# Q32M210 register map
File version: 1.0
Registers are 32-bit, read-write, no defined reset value unless marked. A register's access mark holds for its fields unless they carry their own. Offsets are from the block's base; [hi:lo] are bit positions; lines under a group give offsets from that group; {n}, {i} and the like mark numbered series.

## Nested_Vector_Interrupt_Controller
Base 0xE000E004
0x00 NVIC_INT_TYPE — NVIC Interrupt Controller Type Register
  [4:0] INTLINESNUM — Number of interrupt inputs in steps of 32
    1=NVIC_INTLINESNUM_33_64 (33 to 64 interrupt inputs)
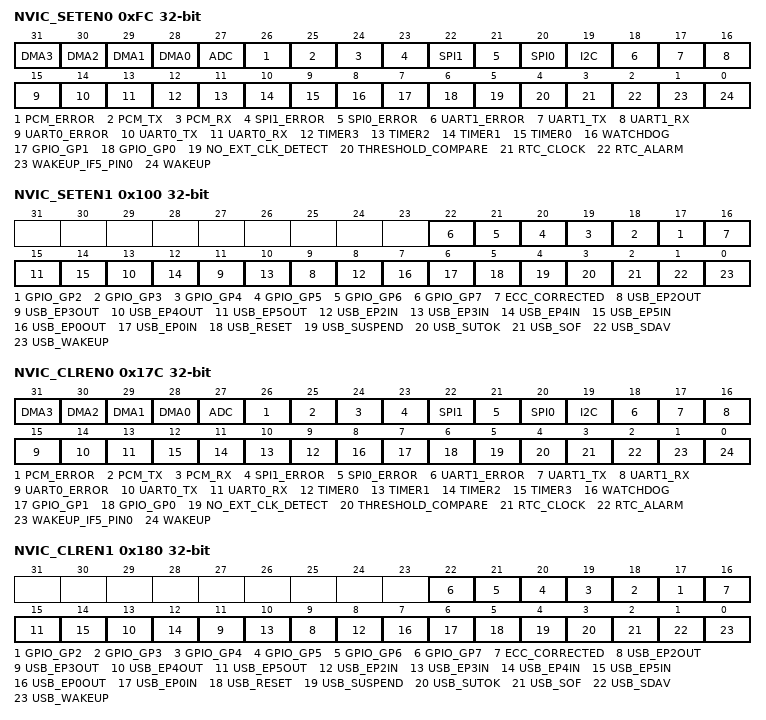
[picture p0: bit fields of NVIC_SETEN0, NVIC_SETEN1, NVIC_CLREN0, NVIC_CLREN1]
0xFC NVIC_SETEN0 — NVIC External Interrupt Set Enable Register 0
  [n+28] DMA{n} (n=0..3) — DMA channel {n} interrupt set enable
    1=NVIC_DMA{n}_INT_ENABLE (Enable DMA channel {n} interrupt)
  [27] ADC — ADC interrupt set enable
    1=NVIC_ADC_INT_ENABLE (Enable ADC0interrupt)
  [26] PCM_ERROR — PCM buffer overflow/underrun interrupt set enable
    1=NVIC_PCM_ERROR_INT_ENABLE (Enable PCM error interrupt)
  [25] PCM_TX — PCM transmit interrupt set enable
    1=NVIC_PCM_TX_INT_ENABLE (Enable PCM TX interrupt)
  [24] PCM_RX — PCM receive interrupt set enable
    1=NVIC_PCM_RX_INT_ENABLE (Enable PCM RX interrupt)
  [23] SPI1_ERROR — SPI1 buffer overflow/underrun error interrupt set enable
    1=NVIC_SPI1_ERROR_INT_ENABLE (Enable SPI1 error interrupt)
  [22] SPI1 — SPI1 interrupt set enable
    1=NVIC_SPI1_INT_ENABLE (Enable SPI1 interrupt)
  [21] SPI0_ERROR — SPI0 buffer overflow/underrun error interrupt set enable
    1=NVIC_SPI0_ERROR_INT_ENABLE (Enable SPI0 error interrupt)
  [20] SPI0 — SPI0 interrupt set enable
    1=NVIC_SPI0_INT_ENABLE (Enable SPI0 interrupt)
  [19] I2C — I2C interrupt set enable
    1=NVIC_I2C_INT_ENABLE (Enable I2C interrupt)
  [18] UART1_ERROR — UART1 buffer overflow/underrun error interrupt set enable
    1=NVIC_UART1_ERROR_INT_ENABLE (Enable UART1 error interrupt)
  [17] UART1_TX — UART1 transmit interrupt set enable
    1=NVIC_UART1_TX_INT_ENABLE (Enable UART1 transmit interrupt)
  [16] UART1_RX — UART1 receive interrupt set enable
    1=NVIC_UART1_RX_INT_ENABLE (Enable UART1 receive interrupt)
  [15] UART0_ERROR — UART0 buffer overflow/underrun error interrupt set enable
    1=NVIC_UART0_ERROR_INT_ENABLE (Enable UART0 error interrupt)
  [14] UART0_TX — UART0 transmit interrupt set enable
    1=NVIC_UART0_TX_INT_ENABLE (Enable UART0 transmit interrupt)
  [13] UART0_RX — UART0 receive interrupt set enable
    1=NVIC_UART0_RX_INT_ENABLE (Enable UART0 receive interrupt)
  [12] TIMER3 — TIMER1 interrupt set enable
    1=NVIC_TIMER3_INT_ENABLE (Enable TIMER1 interrupt)
  [11] TIMER2 — TIMER0 interrupt set enable
    1=NVIC_TIMER2_INT_ENABLE (Enable TIMER0 interrupt)
  [10] TIMER1 — TIMER1 interrupt set enable
    1=NVIC_TIMER1_INT_ENABLE (Enable TIMER1 interrupt)
  [9] TIMER0 — TIMER0 interrupt set enable
    1=NVIC_TIMER0_INT_ENABLE (Enable TIMER0 interrupt)
  [8] WATCHDOG — Watchdog interrupt set enable
    1=NVIC_WATCHDOG_INT_ENABLE (Enable watchdog interrupt)
  [7] GPIO_GP1 — GPIO_GP1 interrupt set enable
    1=NVIC_GPIO_GP1_INT_ENABLE (Enable GPIO_GP1 interrupt)
  [6] GPIO_GP0 — GPIO_GP0 interrupt set enable
    1=NVIC_GPIO_GP0_INT_ENABLE (Enable GPIO_GP0 interrupt)
  [5] NO_EXT_CLK_DETECT — No external clock interrupt set enable
    1=NVIC_NO_EXT_CLK_DETECT_INT_ENABLE (Enable no external clock interrupt)
  [4] THRESHOLD_COMPARE — Threshold compare interrupt set enable
    1=NVIC_THRESHOLD_COMPARE_INT_ENABLE (Enable threshold compare interrupt)
  [3] RTC_CLOCK — RTC clock interrupt set enable
    1=NVIC_RTC_CLOCK_INT_ENABLE (Enable RTC clock interrupt)
  [2] RTC_ALARM — RTC alarm interrupt set enable
    1=NVIC_RTC_ALARM_INT_ENABLE (Enable RTC alarm interrupt)
  [1] WAKEUP_IF5_PIN0 — Analog wakeup interrupt set enable
    1=NVIC_WAKEUP_IF5_PIN0_INT_ENABLE (Enable analog wakeup interrupt)
  [0] WAKEUP — Wakeup interrupt set enable
    1=NVIC_WAKEUP_INT_ENABLE (Enable wakeup interrupt)
0x100 NVIC_SETEN1 — NVIC External Interrupt Set Enable Register 1
  [n+15] GPIO_GP{n} (n=2..7) — GPIO_GP{n} interrupt set enable
    1=NVIC_GPIO_GP{n}_INT_ENABLE (Enable GPIO_GP{n} interrupt)
  [16] ECC_CORRECTED — ECC error corrected interrupt set enable
    1=NVIC_ECC_CORRECTED_INT_ENABLE (Enable the ECC error corrected interrupt)
  [2n+5] USB_EP{n}OUT (n=2..5) — USB EP{n}OUT interrupt set enable
    1=NVIC_USB_EP{n}OUT_INT_ENABLE (Enable USB EP{n}OUT interrupt)
  [2n+4] USB_EP{n}IN (n=2..5) — USB EP{n}IN interrupt set enable
    1=NVIC_USB_EP{n}IN_INT_ENABLE (Enable USB EP{n}IN interrupt)
  [7] USB_EP0OUT — USB EP0OUT interrupt set enable
    1=NVIC_USB_EP0OUT_INT_ENABLE (Enable USB EP0OUT interrupt)
  [6] USB_EP0IN — USB EP0IN interrupt set enable
    1=NVIC_USB_EP0IN_INT_ENABLE (Enable USB EP0IN interrupt)
  [5] USB_RESET — USB reset interrupt set enable
    1=NVIC_USB_RESET_INT_ENABLE (Enable USB reset interrupt)
  [4] USB_SUSPEND — USB suspend interrupt set enable
    1=NVIC_USB_SUSPEND_INT_ENABLE (Enable USB suspend interrupt)
  [3] USB_SUTOK — USB setup data loading interrupt set enable
    1=NVIC_USB_SUTOK_INT_ENABLE (Enable USB setup data loading interrupt)
  [2] USB_SOF — USB start of frame interrupt set enable
    1=NVIC_USB_SOF_INT_ENABLE (Enable USB start of frame interrupt)
  [1] USB_SDAV — USB setup data available interrupt set enable
    1=NVIC_USB_SDAV_INT_ENABLE (Enable USB setup data available interrupt)
  [0] USB_WAKEUP — USB wakeup interrupt set enable
    1=NVIC_USB_WAKEUP_INT_ENABLE (Enable USB wakeup interrupt)
0x17C NVIC_CLREN0 — NVIC External Interrupt Clear Enable Register 0
  [n+28] DMA{n} (n=0..3) — DMA channel {n} interrupt clear enable
    1=NVIC_DMA{n}_INT_DISABLE (Disable DMA channel {n} interrupt)
  [27] ADC — ADC interrupt clear enable
    1=NVIC_ADC_INT_DISABLE (Disable ADC interrupt)
  [26] PCM_ERROR — PCM buffer overflow/underrun interrupt clear enable
    1=NVIC_PCM_ERROR_INT_DISABLE (Disable PCM error interrupt)
  [25] PCM_TX — PCM transmit interrupt clear enable
    1=NVIC_PCM_TX_INT_DISABLE (Disable PCM TX interrupt)
  [24] PCM_RX — PCM receive interrupt clear enable
    1=NVIC_PCM_RX_INT_DISABLE (Disable PCM RX interrupt)
  [23] SPI1_ERROR — SPI1 buffer overflow/underrun error interrupt clear enable
    1=NVIC_SPI1_ERROR_INT_DISABLE (Disable SPI1 error interrupt)
  [22] SPI1 — SPI1 interrupt clear enable
    1=NVIC_SPI1_INT_DISABLE (Disable SPI1 interrupt)
  [21] SPI0_ERROR — SPI0 buffer overflow/underrun error interrupt clear enable
    1=NVIC_SPI0_ERROR_INT_DISABLE (Disable SPI0 error interrupt)
  [20] SPI0 — SPI0 interrupt clear enable
    1=NVIC_SPI0_INT_DISABLE (Disable SPI0 interrupt)
  [19] I2C — I2C interrupt clear enable
    1=NVIC_I2C_INT_DISABLE (Disable I2C interrupt)
  [18] UART1_ERROR — UART1 buffer overflow/underrun error interrupt clear enable
    1=NVIC_UART1_ERROR_INT_DISABLE (Disable UART1 error interrupt)
  [17] UART1_TX — UART1 transmit interrupt clear enable
    1=NVIC_UART1_TX_INT_DISABLE (Disable UART1 transmit interrupt)
  [16] UART1_RX — UART1 receive interrupt clear enable
    1=NVIC_UART1_RX_INT_DISABLE (Disable UART1 receive interrupt)
  [15] UART0_ERROR — UART0 buffer overflow/underrun error interrupt clear enable
    1=NVIC_UART0_ERROR_INT_DISABLE (Disable UART0 error interrupt)
  [14] UART0_TX — UART0 transmit interrupt clear enable
    1=NVIC_UART0_TX_INT_DISABLE (Disable UART0 transmit interrupt)
  [13] UART0_RX — UART0 receive interrupt clear enable
    1=NVIC_UART0_RX_INT_DISABLE (Disable UART0 receive interrupt)
  [n+9] TIMER{n} (n=0..3) — TIMER{n} interrupt clear enable
    1=NVIC_TIMER{n}_INT_DISABLE (Disable TIMER{n} interrupt)
  [8] WATCHDOG — Watchdog interrupt clear enable
    1=NVIC_WATCHDOG_INT_DISABLE (Disable watchdog interrupt)
  [7] GPIO_GP1 — GPIO_GP1 interrupt clear enable
    1=NVIC_GPIO_GP1_INT_DISABLE (Disable GPIO_GP1 interrupt)
  [6] GPIO_GP0 — GPIO_GP0 interrupt clear enable
    1=NVIC_GPIO_GP0_INT_DISABLE (Disable GPIO_GP0 interrupt)
  [5] NO_EXT_CLK_DETECT — No external clock interrupt clear enable
    1=NVIC_NO_EXT_CLK_DETECT_INT_DISABLE (Disable no external clock interrupt)
  [4] THRESHOLD_COMPARE — Threshold compare interrupt clear enable
    1=NVIC_THRESHOLD_COMPARE_INT_DISABLE (Disable threshold compare interrupt)
  [3] RTC_CLOCK — RTC clock interrupt clear enable
    1=NVIC_RTC_CLOCK_INT_DISABLE (Disable RTC clock interrupt)
  [2] RTC_ALARM — RTC alarm interrupt clear enable
    1=NVIC_RTC_ALARM_INT_DISABLE (Disable RTC alarm interrupt)
  [1] WAKEUP_IF5_PIN0 — Analog wakeup interrupt clear enable
    1=NVIC_WAKEUP_IF5_PIN0_INT_DISABLE (Disable analog wakeup interrupt)
  [0] WAKEUP — Wakeup interrupt clear enable
    1=NVIC_WAKEUP_INT_DISABLE (Disable wakeup interrupt)
0x180 NVIC_CLREN1 — NVIC External Interrupt Clear Enable Register 1
  [n+15] GPIO_GP{n} (n=2..7) — GPIO_GP{n} interrupt clear enable
    1=NVIC_GPIO_GP{n}_INT_DISABLE (Disable GPIO_GP{n} interrupt)
  [16] ECC_CORRECTED — ECC error corrected interrupt clear enable
    1=NVIC_ECC_CORRECTED_INT_DISABLE (Disable the ECC error corrected interrupt)
  [2n+5] USB_EP{n}OUT (n=2..5) — USB EP{n}OUT interrupt clear enable
    1=NVIC_USB_EP{n}OUT_INT_DISABLE (Disable USB EP{n}OUT interrupt)
  [2n+4] USB_EP{n}IN (n=2..5) — USB EP{n}IN interrupt clear enable
    1=NVIC_USB_EP{n}IN_INT_DISABLE (Disable USB EP{n}IN interrupt)
  [7] USB_EP0OUT — USB EP0OUT interrupt clear enable
    1=NVIC_USB_EP0OUT_INT_DISABLE (Disable USB EP0OUT interrupt)
  [6] USB_EP0IN — USB EP0IN interrupt clear enable
    1=NVIC_USB_EP0IN_INT_DISABLE (Disable USB EP0IN interrupt)
  [5] USB_RESET — USB reset interrupt clear enable
    1=NVIC_USB_RESET_INT_DISABLE (Disable USB reset interrupt)
  [4] USB_SUSPEND — USB suspend interrupt clear enable
    1=NVIC_USB_SUSPEND_INT_DISABLE (Disable USB suspend interrupt)
  [3] USB_SUTOK — USB setup data loading interrupt clear enable
    1=NVIC_USB_SUTOK_INT_DISABLE (Disable USB setup data loading interrupt)
  [2] USB_SOF — USB start of frame interrupt clear enable
    1=NVIC_USB_SOF_INT_DISABLE (Disable USB start of frame interrupt)
  [1] USB_SDAV — USB setup data available interrupt clear enable
    1=NVIC_USB_SDAV_INT_DISABLE (Disable USB setup data available interrupt)
  [0] USB_WAKEUP — USB wakeup interrupt clear enable
    1=NVIC_USB_WAKEUP_INT_DISABLE (Disable USB wakeup interrupt)
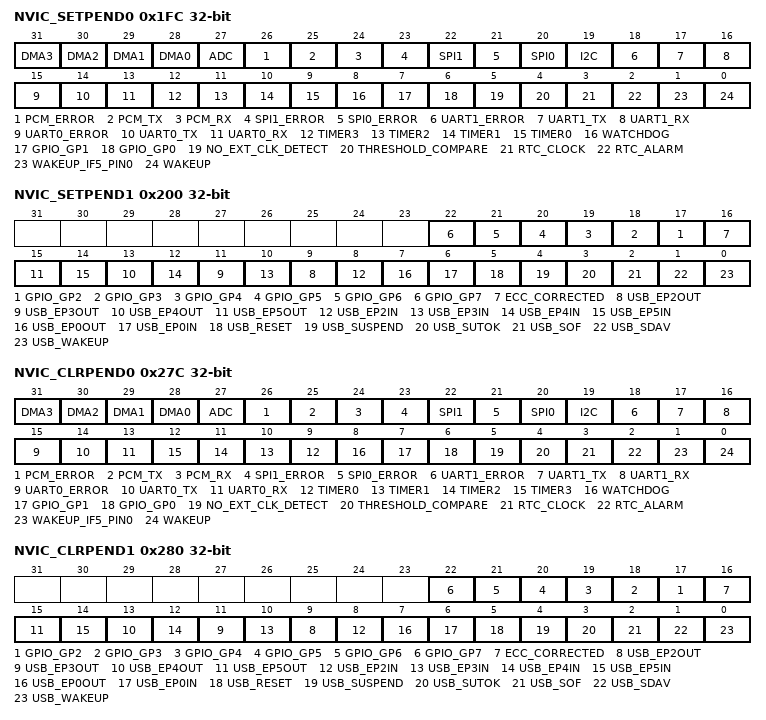
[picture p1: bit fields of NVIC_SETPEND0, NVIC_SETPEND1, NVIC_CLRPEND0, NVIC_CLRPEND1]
0x1FC NVIC_SETPEND0 — NVIC External Interrupt Set Pending Register 0
  [n+28] DMA{n} (n=0..3) — DMA channel {n} interrupt set pending
    1=NVIC_DMA{n}_INT_SETPEND (Set DMA channel {n} interrupt as pending)
  [27] ADC — ADC interrupt set pending
    1=NVIC_ADC_INT_SETPEND (Set ADC interrupt as pending)
  [26] PCM_ERROR — PCM buffer overflow/underrun interrupt set pending
    1=NVIC_PCM_ERROR_INT_SETPEND (Set PCM error interrupt as pending)
  [25] PCM_TX — PCM transmit interrupt set pending
    1=NVIC_PCM_TX_INT_SETPEND (Set PCM TX interrupt as pending)
  [24] PCM_RX — PCM receive interrupt set pending
    1=NVIC_PCM_RX_INT_SETPEND (Set PCM RX interrupt as pending)
  [23] SPI1_ERROR — SPI1 buffer overflow/underrun error interrupt set pending
    1=NVIC_SPI1_ERROR_INT_SETPEND (Set SPI1 error interrupt as pending)
  [22] SPI1 — SPI1 interrupt set pending
    1=NVIC_SPI1_INT_SETPEND (Set SPI1 interrupt as pending)
  [21] SPI0_ERROR — SPI0 buffer overflow/underrun error interrupt set pending
    1=NVIC_SPI0_ERROR_INT_SETPEND (Set SPI0 error interrupt as pending)
  [20] SPI0 — SPI0 interrupt set pending
    1=NVIC_SPI0_INT_SETPEND (Set SPI0 interrupt as pending)
  [19] I2C — I2C interrupt set pending
    1=NVIC_I2C_INT_SETPEND (Set I2C interrupt as pending)
  [18] UART1_ERROR — UART1 buffer overflow/underrun error interrupt set pending
    1=NVIC_UART1_ERROR_INT_SETPEND (Set UART1 error interrupt as pending)
  [17] UART1_TX — UART1 transmit interrupt set pending
    1=NVIC_UART1_TX_INT_SETPEND (Set UART1 transmit interuppt as pending)
  [16] UART1_RX — UART1 receive interrupt set pending
    1=NVIC_UART1_RX_INT_SETPEND (Set UART1 receive interrupt as pending)
  [15] UART0_ERROR — UART0 buffer overflow/underrun error interrupt set pending
    1=NVIC_UART0_ERROR_INT_SETPEND (Set UART0 error interrupt as pending)
  [14] UART0_TX — UART0 transmit interrupt set pending
    1=NVIC_UART0_TX_INT_SETPEND (Set UART0 transmit interrupt as pending)
  [13] UART0_RX — UART0 receive interrupt set pending
    1=NVIC_UART0_RX_INT_SETPEND (Set UART0 receive interrupt as pending)
  [12] TIMER3 — TIMER3 interrupt set pending
    1=NVIC_TIMER3_INT_SETPEND (SetTIMER3 interrupt as pending)
  [11] TIMER2 — TIMER2 interrupt set pending
    1=NVIC_TIMER2_INT_SETPEND (Set TIMER2 interrupt as pending)
  [10] TIMER1 — TIMER1 interrupt set pending
    1=NVIC_TIMER1_INT_SETPEND (SetTIMER1 interrupt as pending)
  [9] TIMER0 — TIMER0 interrupt set pending
    1=NVIC_TIMER0_INT_SETPEND (Set TIMER0 interrupt as pending)
  [8] WATCHDOG — Watchdog interrupt set pending
    1=NVIC_WATCHDOG_INT_SETPEND (Set watchdog interrupt as pending)
  [7] GPIO_GP1 — GPIO_GP1 interrupt set pending
    1=NVIC_GPIO_GP1_INT_SETPEND (Set GPIO_GP1 interrupt as pending)
  [6] GPIO_GP0 — GPIO_GP0 interrupt set pending
    1=NVIC_GPIO_GP0_INT_SETPEND (Set GPIO_GP0 interrupt as pending)
  [5] NO_EXT_CLK_DETECT — No external clock interrupt set pending
    1=NVIC_NO_EXT_CLK_DETECT_INT_SETPEND (Set no external clock interrupt as pending)
  [4] THRESHOLD_COMPARE — Threshold compare interrupt set pending
    1=NVIC_THRESHOLD_COMPARE_INT_SETPEND (Set threshold compare interrupt as pending)
  [3] RTC_CLOCK — RTC clock interrupt set pending
    1=NVIC_RTC_CLOCK_INT_SETPEND (Set RTC clock interrupt as pending)
  [2] RTC_ALARM — RTC alarm interrupt set pending
    1=NVIC_RTC_ALARM_INT_SETPEND (Set RTC alarm interrupt as pending)
  [1] WAKEUP_IF5_PIN0 — Analog wakeup interrupt set pending
    1=NVIC_WAKEUP_IF5_PIN0_INT_SETPEND (Set analog wakeup interrupt as pending)
  [0] WAKEUP — Wakeup interrupt set pending
    1=NVIC_WAKEUP_INT_SETPEND (Set wakeup interrupt as pending)
0x200 NVIC_SETPEND1 — NVIC External Interrupt Set Pending Register 1
  [n+15] GPIO_GP{n} (n=2..7) — GPIO_GP{n} interrupt set pending
    1=NVIC_GPIO_GP{n}_INT_SETPEND (Set GPIO_GP{n} interrupt as pending)
  [16] ECC_CORRECTED — ECC error corrected interrupt set pending
    1=NVIC_ECC_CORRECTED_INT_SETPEND (Set the ECC error corrected interrupt as pending)
  [2n+5] USB_EP{n}OUT (n=2..5) — USB EP{n}OUT interrupt set pending
    1=NVIC_USB_EP{n}OUT_INT_SETPEND (Set USB EP{n}OUT interrupt as pending)
  [2n+4] USB_EP{n}IN (n=2..5) — USB EP{n}IN interrupt set pending
    1=NVIC_USB_EP{n}IN_INT_SETPEND (Set USB EP{n}IN interrupt as pending)
  [7] USB_EP0OUT — USB EP0OUT interrupt set pending
    1=NVIC_USB_EP0OUT_INT_SETPEND (Set USB EP0OUT interrupt as pending)
  [6] USB_EP0IN — USB EP0IN interrupt set pending
    1=NVIC_USB_EP0IN_INT_SETPEND (Set USB EP0IN interrupt as pending)
  [5] USB_RESET — USB reset interrupt set pending
    1=NVIC_USB_RESET_INT_SETPEND (Set USB reset interrupt as pending)
  [4] USB_SUSPEND — USB suspend interrupt set pending
    1=NVIC_USB_SUSPEND_INT_SETPEND (Set USB suspend interrupt as pending)
  [3] USB_SUTOK — USB setup data loading interrupt set pending
    1=NVIC_USB_SUTOK_INT_SETPEND (Set USB setup data loading interrupt as pending)
  [2] USB_SOF — USB start of frame interrupt set pending
    1=NVIC_USB_SOF_INT_SETPEND (Set USB start of frame interrupt as pending)
  [1] USB_SDAV — USB setup data available interrupt set pending
    1=NVIC_USB_SDAV_INT_SETPEND (Set USB setup data interrupt as pending)
  [0] USB_WAKEUP — USB wakeup interrupt set pending
    1=NVIC_USB_WAKEUP_INT_SETPEND (Set USB wakeup interrupt as pending)
0x27C NVIC_CLRPEND0 — NVIC External Interrupt Clear Pending Register 0
  [n+28] DMA{n} (n=0..3) — DMA channel {n} interrupt clear pending
    1=NVIC_DMA{n}_INT_CLRPEND (Clear pending DMA channel {n} interrupt)
  [27] ADC — ADC interrupt clear pending
    1=NVIC_ADC_INT_CLRPEND (Clear pending ADC interrupt)
  [26] PCM_ERROR — PCM buffer overflow/underrun interrupt clear pending
    1=NVIC_PCM_ERROR_INT_CLRPEND (Clear pending PCM error interrupt)
  [25] PCM_TX — PCM transmit interrupt clear pending
    1=NVIC_PCM_TX_INT_CLRPEND (Clear pending PCM TX interrupt)
  [24] PCM_RX — PCM receive interrupt clear pending
    1=NVIC_PCM_RX_INT_CLRPEND (Clear pending PCM RX interrupt)
  [23] SPI1_ERROR — SPI1 buffer overflow/underrun error interrupt clear pending
    1=NVIC_SPI1_ERROR_INT_CLRPEND (Clear pending SPI1 error interrupt)
  [22] SPI1 — SPI1 interrupt clear pending
    1=NVIC_SPI1_INT_CLRPEND (Clear pending SPI1 interrupt)
  [21] SPI0_ERROR — SPI0 buffer overflow/underrun error interrupt clear pending
    1=NVIC_SPI0_ERROR_INT_CLRPEND (Clear pending SPI0 error interrupt)
  [20] SPI0 — SPI0 interrupt clear pending
    1=NVIC_SPI0_INT_CLRPEND (Clear pending SPI0 interrupt)
  [19] I2C — I2C interrupt clear pending
    1=NVIC_I2C_INT_CLRPEND (Clear pending I2C interrupt)
  [18] UART1_ERROR — UART1 buffer overflow/underrun error interrupt clear pending
    1=NVIC_UART1_ERROR_INT_CLRPEND (Clear pending UART1 error interrupt)
  [17] UART1_TX — UART1 transmit interrupt clear pending
    1=NVIC_UART1_TX_INT_CLRPEND (Clear pending UART1 transmit interrupt)
  [16] UART1_RX — UART1 receive interrupt clear pending
    1=NVIC_UART1_RX_INT_CLRPEND (Clear pending UART1 receive interrupt)
  [15] UART0_ERROR — UART0 buffer overflow/underrun error interrupt clear pending
    1=NVIC_UART0_ERROR_INT_CLRPEND (Clear pending UART0 error interrupt)
  [14] UART0_TX — UART0 transmit interrupt clear pending
    1=NVIC_UART0_TX_INT_CLRPEND (Clear pending UART0 transmit interrupt)
  [13] UART0_RX — UART0 receive interrupt clear pending
    1=NVIC_UART0_RX_INT_CLRPEND (Clear pending UART0 receive interrupt)
  [n+9] TIMER{n} (n=0..3) — TIMER{n} interrupt clear pending
    1=NVIC_TIMER{n}_INT_CLRPEND (Clear pending TIMER{n} interrupt)
  [8] WATCHDOG — Watchdog interrupt clear pending
    1=NVIC_WATCHDOG_INT_CLRPEND (Clear pending watchdog interrupt)
  [7] GPIO_GP1 — GPIO_GP1 interrupt clear pending
    1=NVIC_GPIO_GP1_INT_CLRPEND (Clear pending GPIO_GP1 interrupt)
  [6] GPIO_GP0 — GPIO_GP0 interrupt clear pending
    1=NVIC_GPIO_GP0_INT_CLRPEND (Clear pending GPIO_GP0 interrupt)
  [5] NO_EXT_CLK_DETECT — No external clock interrupt clear pending
    1=NVIC_NO_EXT_CLK_DETECT_INT_CLRPEND (Clear no external clock interrupt)
  [4] THRESHOLD_COMPARE — Threshold compare interrupt clear pending
    1=NVIC_THRESHOLD_COMPARE_INT_CLRPEND (Clear threshold compare interrupt)
  [3] RTC_CLOCK — RTC clock interrupt clear pending
    1=NVIC_RTC_CLOCK_INT_CLRPEND (Clear RTC clock interrupt)
  [2] RTC_ALARM — RTC alarm interrupt clear pending
    1=NVIC_RTC_ALARM_INT_CLRPEND (Clear RTC alarm interrupt)
  [1] WAKEUP_IF5_PIN0 — Analog wakeup interrupt clear pending
    1=NVIC_WAKEUP_IF5_PIN0_INT_CLRPEND (Clear pending analog wakeup interrupt)
  [0] WAKEUP — Wakeup interrupt clear pending
    1=NVIC_WAKEUP_INT_CLRPEND (Clear pending wakeup interrupt)
0x280 NVIC_CLRPEND1 — NVIC External Interrupt Clear Pending Register 1
  [n+15] GPIO_GP{n} (n=2..7) — GPIO_GP{n} interrupt clear pending
    1=NVIC_GPIO_GP{n}_INT_CLRPEND (Clear pending GPIO_GP{n} interrupt)
  [16] ECC_CORRECTED — ECC error corrected interrupt clear pending
    1=NVIC_ECC_CORRECTED_INT_CLRPEND (Clear pending ECC error corrected interrupt)
  [2n+5] USB_EP{n}OUT (n=2..5) — USB EP{n}OUT interrupt clear pending
    1=NVIC_USB_EP{n}OUT_INT_CLRPEND (Clear pending USB EP{n}OUT interrupt)
  [2n+4] USB_EP{n}IN (n=2..5) — USB EP{n}IN interrupt clear pending
    1=NVIC_USB_EP{n}IN_INT_CLRPEND (Clear pending USB EP{n}IN interrupt)
  [7] USB_EP0OUT — USB EP0OUT interrupt clear pending
    1=NVIC_USB_EP0OUT_INT_CLRPEND (Clear pending USB EP0OUT interrupt)
  [6] USB_EP0IN — USB EP0IN interrupt clear pending
    1=NVIC_USB_EP0IN_INT_CLRPEND (Clear pending USB EP0IN interrupt)
  [5] USB_RESET — USB set interrupt clear pending
    1=NVIC_USB_RESET_INT_CLRPEND (Clear pending USB reset interrupt)
  [4] USB_SUSPEND — USB suspend interrupt clear pending
    1=NVIC_USB_SUSPEND_INT_CLRPEND (Clear pending USB suspend interrupt)
  [3] USB_SUTOK — USB setup data loading interrupt clear pending
    1=NVIC_USB_SUTOK_INT_CLRPEND (Clear pending USB setup data loading interrupt)
  [2] USB_SOF — USB start of frame interrupt clear pending
    1=NVIC_USB_SOF_INT_CLRPEND (Clear pending USB start of frame interrupt)
  [1] USB_SDAV — USB setup data available interrupt clear pending
    1=NVIC_USB_SDAV_INT_CLRPEND (Clear pending USB setup data available interrupt)
  [0] USB_WAKEUP — USB wakeup interrupt clear pending
    1=NVIC_USB_WAKEUP_INT_CLRPEND (Clear pending USB wakeup interrupt)
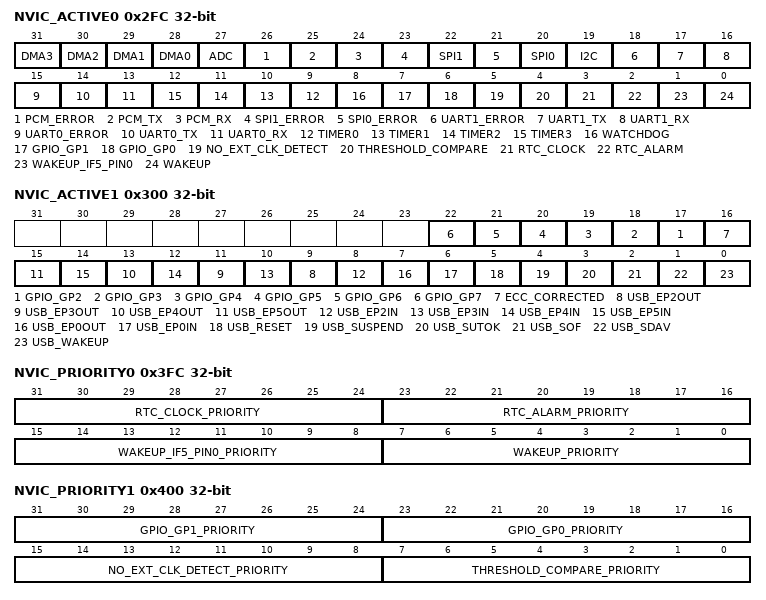
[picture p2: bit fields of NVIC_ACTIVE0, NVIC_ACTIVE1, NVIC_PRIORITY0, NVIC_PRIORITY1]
0x2FC NVIC_ACTIVE0 — NVIC External Interrupt Active Register 0
  [n+28] DMA{n} (n=0..3) — DMA channel {n} interrupt active status
    1=NVIC_DMA{n}_INT_ACTIVE (DMA channel {n} interrupt is active)
  [27] ADC — ADC interrupt active status
    1=NVIC_ADC_INT_ACTIVE (ADC interrupt is active)
  [26] PCM_ERROR — PCM buffer overflow/underrun interrupt active status
    1=NVIC_PCM_ERROR_INT_ACTIVE (PCM error interrupt is active)
  [25] PCM_TX — PCM transmit interrupt active status
    1=NVIC_PCM_TX_INT_ACTIVE (PCM TX interrupt is active)
  [24] PCM_RX — PCM receive interrupt active status
    1=NVIC_PCM_RX_INT_ACTIVE (PCM RX interrupt is active)
  [23] SPI1_ERROR — SPI1 buffer overflow/underrun error interrupt active status
    1=NVIC_SPI1_ERROR_INT_ACTIVE (SPI1 error interrupt is active)
  [22] SPI1 — SPI1 interrupt active status
    1=NVIC_SPI1_INT_ACTIVE (SPI1 interrupt is active)
  [21] SPI0_ERROR — SPI0 buffer overflow/underrun error interrupt active status
    1=NVIC_SPI0_ERROR_INT_ACTIVE (SPI0 error interrupt is active)
  [20] SPI0 — SPI0 interrupt active status
    1=NVIC_SPI0_INT_ACTIVE (SPI0 interrupt is active)
  [19] I2C — I2C interrupt active status
    1=NVIC_I2C_INT_ACTIVE (I2C interrupt is active)
  [18] UART1_ERROR — UART1 buffer overflow/underrun error interrupt active status
    1=NVIC_UART1_ERROR_INT_ACTIVE (UART1 error interrupt is active)
  [17] UART1_TX — UART1 transmit interrupt active status
    1=NVIC_UART1_TX_INT_ACTIVE (UART1 transmit interrupt is active)
  [16] UART1_RX — UART1 receive interrupt active status
    1=NVIC_UART1_RX_INT_ACTIVE (UART1 receive interrupt is active)
  [15] UART0_ERROR — UART0 buffer overflow/underrun error interrupt active status
    1=NVIC_UART0_ERROR_INT_ACTIVE (UART0 error interrupt is active)
  [14] UART0_TX — UART0 transmit interrupt active status
    1=NVIC_UART0_TX_INT_ACTIVE (UART0 transmit interrupt is active)
  [13] UART0_RX — UART0 receive interrupt active status
    1=NVIC_UART0_RX_INT_ACTIVE (UART0 receive interrupt is active)
  [n+9] TIMER{n} (n=0..3) — TIMER{n} interrupt active status
    1=NVIC_TIMER{n}_INT_ACTIVE (TIMER{n} interrupt is active)
  [8] WATCHDOG — Watchdog interrupt active status
    1=NVIC_WATCHDOG_INT_ACTIVE (Watchdog interrupt is active)
  [7] GPIO_GP1 — GPIO_GP1 interrupt active status
    1=NVIC_GPIO_GP1_INT_ACTIVE (GPIO_GP1 interrupt is active)
  [6] GPIO_GP0 — GPIO_GP0 interrupt active status
    1=NVIC_GPIO_GP0_INT_ACTIVE (GPIO_GP0 interrupt is active)
  [5] NO_EXT_CLK_DETECT — No external clock interrupt active status
    1=NVIC_NO_EXT_CLK_DETECT_INT_ACTIVE (No external clock interrupt is active)
  [4] THRESHOLD_COMPARE — Threshold compare interrupt active status
    1=NVIC_THRESHOLD_COMPARE_INT_ACTIVE (Threshold compare interrupt is active)
  [3] RTC_CLOCK — RTC clock interrupt active status
    1=NVIC_RTC_CLOCK_INT_ACTIVE (RTC clock interrupt is active)
  [2] RTC_ALARM — RTC alarm interrupt active status
    1=NVIC_RTC_ALARM_INT_ACTIVE (RTC alarm interrupt is active)
  [1] WAKEUP_IF5_PIN0 — Analog wakeup interrupt active status
    1=NVIC_WAKEUP_IF5_PIN0_INT_ACTIVE (Analog wakeup interrupt is active)
  [0] WAKEUP — Wakeup interrupt active status
    1=NVIC_WAKEUP_INT_ACTIVE (Wakeup interrupt is active)
0x300 NVIC_ACTIVE1 — NVIC External Interrupt Active Register 1
  [n+15] GPIO_GP{n} (n=2..7) — GPIO_GP{n} interrupt active status
    1=NVIC_GPIO_GP{n}_INT_ACTIVE (GPIO_GP{n} interrupt is active)
  [16] ECC_CORRECTED — ECC error corrected interrupt active status
    1=NVIC_ECC_CORRECTED_INT_ACTIVE (ECC error corrected interrupt is active)
  [2n+5] USB_EP{n}OUT (n=2..5) — USB EP{n}OUT interrupt active status
    1=NVIC_USB_EP{n}OUT_INT_ACTIVE (USB EP{n}OUT interrupt is active)
  [2n+4] USB_EP{n}IN (n=2..5) — USB EP{n}IN interrupt active status
    1=NVIC_USB_EP{n}IN_INT_ACTIVE (USB EP{n}IN interrupt is active)
  [7] USB_EP0OUT — USB EP0OUT interrupt active status
    1=NVIC_USB_EP0OUT_INT_ACTIVE (USB EP0OUT interrupt is active)
  [6] USB_EP0IN — USB EP0IN interrupt active status
    1=NVIC_USB_EP0IN_INT_ACTIVE (USB EP0IN interrupt is active)
  [5] USB_RESET — USB set interrupt active status
    1=NVIC_USB_RESET_INT_ACTIVE (USB reset interrupt is active)
  [4] USB_SUSPEND — USB suspend interrupt active status
    1=NVIC_USB_SUSPEND_INT_ACTIVE (USB suspend interrupt is active)
  [3] USB_SUTOK — USB setup data loading interrupt active status
    1=NVIC_USB_SUTOK_INT_ACTIVE (USB setup data loading interrupt is active)
  [2] USB_SOF — USB start of frame interrupt active status
    1=NVIC_USB_SOF_INT_ACTIVE (USB start of frame interrupt is active)
  [1] USB_SDAV — USB setup data available interrupt active status
    1=NVIC_USB_SDAV_INT_ACTIVE (USB setup data available interrupt is active)
  [0] USB_WAKEUP — USB wakeup interrupt active status
    1=NVIC_USB_WAKEUP_INT_ACTIVE (USB wakeup interrupt is active)
0x3FC NVIC_PRIORITY0 — NVIC External Interrupt Priority Register 0
  [31:24] RTC_CLOCK_PRIORITY, [23:16] RTC_ALARM_PRIORITY, [15:8] WAKEUP_IF5_PIN0_PRIORITY, [7:0] WAKEUP_PRIORITY
0x400 NVIC_PRIORITY1 — NVIC External Interrupt Priority Register 1
  [31:24] GPIO_GP1_PRIORITY, [23:16] GPIO_GP0_PRIORITY, [15:8] NO_EXT_CLK_DETECT_PRIORITY, [7:0] THRESHOLD_COMPARE_PRIORITY
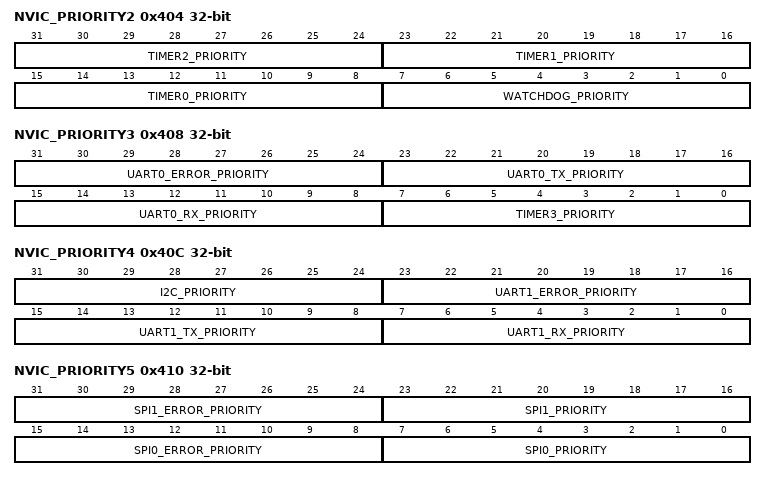
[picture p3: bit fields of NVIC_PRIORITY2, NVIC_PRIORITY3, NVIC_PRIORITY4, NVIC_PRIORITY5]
0x404 NVIC_PRIORITY2 — NVIC External Interrupt Priority Register 2
  [31:24] TIMER2_PRIORITY, [23:16] TIMER1_PRIORITY, [15:8] TIMER0_PRIORITY, [7:0] WATCHDOG_PRIORITY
0x408 NVIC_PRIORITY3 — NVIC External Interrupt Priority Register 3
  [31:24] UART0_ERROR_PRIORITY, [23:16] UART0_TX_PRIORITY, [15:8] UART0_RX_PRIORITY, [7:0] TIMER3_PRIORITY
0x40C NVIC_PRIORITY4 — NVIC External Interrupt Priority Register 4
  [31:24] I2C_PRIORITY, [23:16] UART1_ERROR_PRIORITY, [15:8] UART1_TX_PRIORITY, [7:0] UART1_RX_PRIORITY
0x410 NVIC_PRIORITY5 — NVIC External Interrupt Priority Register 5
  [31:24] SPI1_ERROR_PRIORITY, [23:16] SPI1_PRIORITY, [15:8] SPI0_ERROR_PRIORITY, [7:0] SPI0_PRIORITY
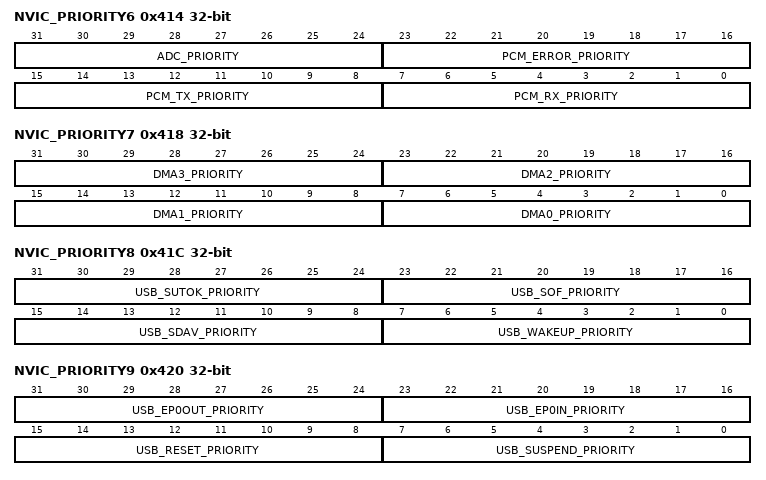
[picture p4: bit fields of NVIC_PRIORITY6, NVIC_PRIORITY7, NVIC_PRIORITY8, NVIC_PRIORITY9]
0x414 NVIC_PRIORITY6 — NVIC External Interrupt Priority Register 6
  [31:24] ADC_PRIORITY, [23:16] PCM_ERROR_PRIORITY, [15:8] PCM_TX_PRIORITY, [7:0] PCM_RX_PRIORITY
0x418 NVIC_PRIORITY7 — NVIC External Interrupt Priority Register 7
  [8n+7:8n] DMA{n}_PRIORITY (n=0..3)
0x41C NVIC_PRIORITY8 — NVIC External Interrupt Priority Register 8
  [31:24] USB_SUTOK_PRIORITY, [23:16] USB_SOF_PRIORITY, [15:8] USB_SDAV_PRIORITY, [7:0] USB_WAKEUP_PRIORITY
0x420 NVIC_PRIORITY9 — NVIC External Interrupt Priority Register 9
  [31:24] USB_EP0OUT_PRIORITY, [23:16] USB_EP0IN_PRIORITY, [15:8] USB_RESET_PRIORITY, [7:0] USB_SUSPEND_PRIORITY
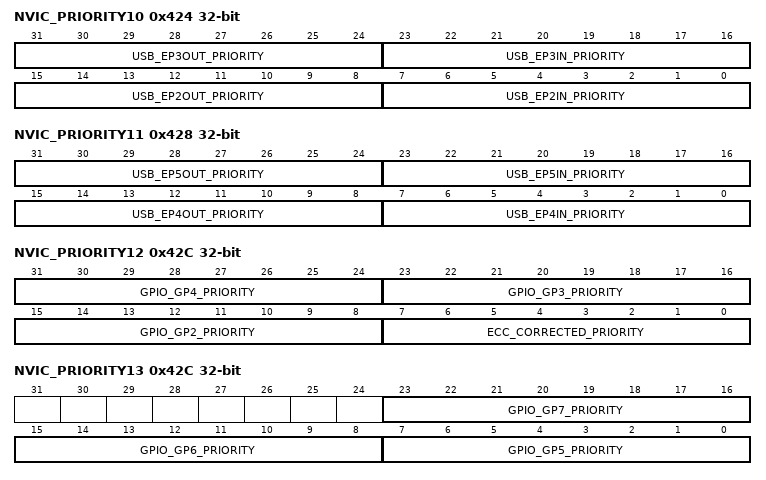
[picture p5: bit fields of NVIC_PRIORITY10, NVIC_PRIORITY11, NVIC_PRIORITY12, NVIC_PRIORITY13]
0x424 NVIC_PRIORITY10 — NVIC External Interrupt Priority Register 10
  [31:24] USB_EP3OUT_PRIORITY, [23:16] USB_EP3IN_PRIORITY, [15:8] USB_EP2OUT_PRIORITY, [7:0] USB_EP2IN_PRIORITY
0x428 NVIC_PRIORITY11 — NVIC External Interrupt Priority Register 11
  [31:24] USB_EP5OUT_PRIORITY, [23:16] USB_EP5IN_PRIORITY, [15:8] USB_EP4OUT_PRIORITY, [7:0] USB_EP4IN_PRIORITY
0x42C NVIC_PRIORITY12 — NVIC External Interrupt Priority Register 12
  [31:24] GPIO_GP4_PRIORITY, [23:16] GPIO_GP3_PRIORITY, [15:8] GPIO_GP2_PRIORITY, [7:0] ECC_CORRECTED_PRIORITY
0x42C NVIC_PRIORITY13 — NVIC External Interrupt Priority Register 13
  [23:16] GPIO_GP7_PRIORITY, [15:8] GPIO_GP6_PRIORITY, [7:0] GPIO_GP5_PRIORITY
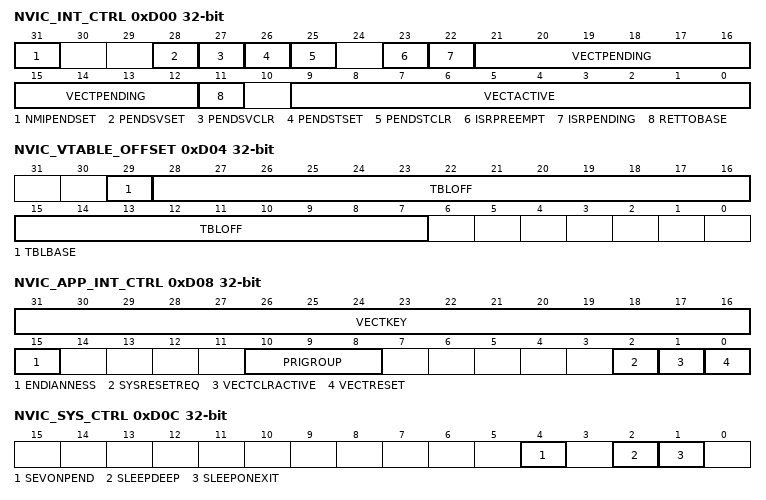
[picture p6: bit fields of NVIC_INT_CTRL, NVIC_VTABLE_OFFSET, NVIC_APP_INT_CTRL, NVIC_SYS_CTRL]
0xD00 NVIC_INT_CTRL — NVIC Interrupt Control and State Register
  [31] NMIPENDSET — Indicates the NMI exception is pending
    1=NVIC_NMI_SETPEND (Set NMI exception to pending)
  [28] PENDSVSET — Write 1 to set pending status for PendSV exception. Read indicates PendSV pending status
    1=NVIC_PENDSV_SETPEND (Set PendSV exception to pending)
  [27] PENDSVCLR — Write 1 to clear PendSV exception pending status
    1=NVIC_PENDSV_CLRPEND (Clear PendSV exception pending status)
  [26] PENDSTSET — Write 1 to set pending status for SYSTICK exception. Read value indicates SYSTICK pending status
    1=NVIC_SYSTICK_SETPEND (Set SYSTICK exception to pending)
  [25] PENDSTCLR — Write 1 to clear SYSTICK exception pending status
    1=NVIC_SYSTICK_CLRPEND (Clear SYSTICK exception pending status)
  [23] ISRPREEMPT — Indicates that a pending interrupt is going to be active in the next step
  [22] ISRPENDING — Indicates that an external interrupt is pending
  [21:12] VECTPENDING — Pending external interrupt number
  [11] RETTOBASE — Set to 1 when the an exception handler is being run.
  [9:0] VECTACTIVE — Number of current running interrupt service routine
0xD04 NVIC_VTABLE_OFFSET — NVIC Vector Table Offset Register
  [29] TBLBASE — Indicates if table base is in code or RAM
    0=NVIC_TBLBASE_CODE (Vector table base is in code memory region); 1=NVIC_TBLBASE_RAM (Vector table base is in SRAM memory region)
  [28:7] TBLOFF — Table offset value in code or RAM region. Must be multiple of 128.
0xD08 NVIC_APP_INT_CTRL — NVIC Application Interrupt and Reset Control Register
  [31:16] VECTKEY — Access key for writing this register. Must be set to 0x05FA to write the other register fields.
    0x5FA=NVIC_VECTKEY_UNLOCK (Unlocks the NVIC_APP_INT_CTRL register); 0xFA05=NVIC_VECTKEY_UNLOCK_READBACK (Readback value when reading the VECTKEY field after unlocking)
  [15] ENDIANNESS — Indicates endianness for data.
    0=NVIC_LITTLE_ENDIAN (Indicates core is configured for little endian data)
  [10:8] PRIGROUP — Priority group setting. Controls how many bits in the priority register are used for pre-empty priority vs. sub-priority.
    3=NVIC_PRIGROUP_4_0 (Indicates 4 bits for pre-emption priority and 0 bits for sub-priority); 4=NVIC_PRIGROUP_3_1 (Indicates 3 bits for pre-emption priority and 1 bit for sub-priority); 5=NVIC_PRIGROUP_2_2 (Indicates 2 bits for pre-emption priority and 2 bits for sub-priority); 6=NVIC_PRIGROUP_1_3 (Indicates 1 bit for pre-emption priority and 3 bits for sub-priority); 7=NVIC_PRIGROUP_0_4 (Indicates 0 bits for pre-emption priority and 4 bits for sub-priority)
  [2] SYSRESETREQ — Requests a chip-level system reset
    1=NVIC_SYSRESET (Requests a chjp-level system reset)
  [1] VECTCLRACTIVE — Clears all active exception state information
    1=NVIC_CLEAR_ACTIVE_VECTORS (Clears all active exception state information)
  [0] VECTRESET — Reset the Cortex-M3
    1=NVIC_VECTRESET (Reset the Cortex-M3)
0xD0C NVIC_SYS_CTRL — NVIC System Control Register
  [4] SEVONPEND — Set to 1 to cause the WFE to wake up if a new interrupt is pended
  [2] SLEEPDEEP — Enable SLEEPDEEP output signal when entering sleep mode
    0=NVIC_SLEEPDEEP_DISABLE (Disable SLEEPDEEP output signal when entering sleep mode); 1=NVIC_SLEEPDEEP_ENABLE (Enable SLEEPDEEP output signal when entering sleep mode)
  [1] SLEEPONEXIT — Enable sleep on exit feature when returning from handler to thread mode
    0=NVIC_SLEEPONEXIT_DISABLE (Disable sleep on exit feature); 1=NVIC_SLEEPONEXIT_ENABLE (Enable sleep on exit feature)
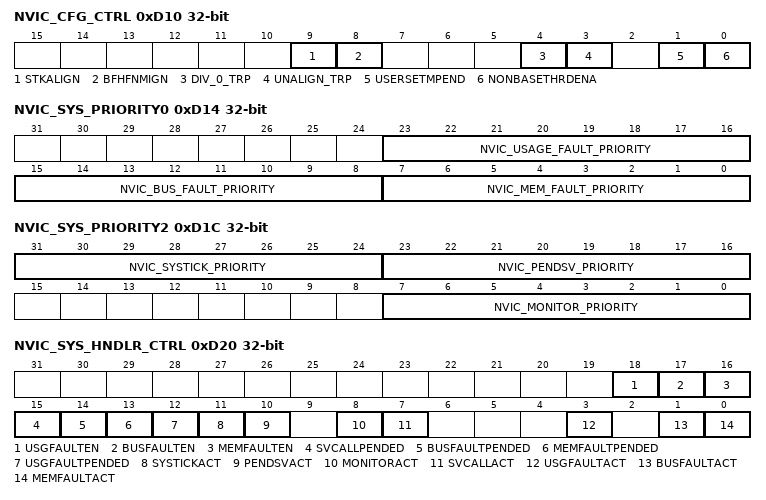
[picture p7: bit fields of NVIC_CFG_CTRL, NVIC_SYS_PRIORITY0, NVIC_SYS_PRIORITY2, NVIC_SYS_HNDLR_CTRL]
0xD10 NVIC_CFG_CTRL — NVIC Configuration Control Register
  [9] STKALIGN — Force stack to be double-word aligned
    0=NVIC_STKALIGN_DISABLE (Disable double-word stack alignment); 1=NVIC_STKALIGN_ENABLE (Enable double-word stack alignment)
  [8] BFHFNMIGN — Ignore data bus faults in hard fault and NMI exceptions
    0=NVIC_BFHFNMIGN_DISABLE (Disable ignoring of data bus faults in hard fault and NMI exception handlers. Bus faults in these handlers will cause lock-up); 1=NVIC_BFHFNMIGN_ENABLE (Enable ignoring of data bus faults in hard fault and NMI exception handlers)
  [4] DIV_0_TRP — Trap on divide by zero
    0=NVIC_DIV_0_TRP_DISABLE (Disable trapping on divide by zero); 1=NVIC_DIV_0_TRP_ENABLE (Enable trapping on divide by zero)
  [3] UNALIGN_TRP — Trap on unaligned data access
    0=NVIC_UNALIGN_TRP_DISABLE (Disable trapping on unaligned data access); 1=NVIC_UNALIGN_TRP_ENABLE (Enable trapping on unaligned data access)
  [1] USERSETMPEND — Allow user code to write to software trigger interrupt register
    0=NVIC_USERSETMPEND_DISABLE (Disable user code access to software trigger interrupt register); 1=NVIC_USERSETMPEND_ENABLE (Enable user code access to software trigger interrupt register)
  [0] NONBASETHRDENA — Non base thread mode enable
    0=NVIC_NONBASETHRDENA_DISABLE (Only allow thread mode on return from last exception); 1=NVIC_NONBASETHRDENA_ENABLE (Allow thread mode from any handler level by controlled return value)
0xD14 NVIC_SYS_PRIORITY0 — NVIC System Interrupt Priority Register 0
  [23:16] NVIC_USAGE_FAULT_PRIORITY, [15:8] NVIC_BUS_FAULT_PRIORITY, [7:0] NVIC_MEM_FAULT_PRIORITY
0xD18 NVIC_SYS_PRIORITY1 — NVIC System Interrupt Priority Register 1
  [31:24] NVIC_SVC_PRIORITY
0xD1C NVIC_SYS_PRIORITY2 — NVIC System Interrupt Priority Register 2
  [31:24] NVIC_SYSTICK_PRIORITY, [23:16] NVIC_PENDSV_PRIORITY, [7:0] NVIC_MONITOR_PRIORITY
0xD20 NVIC_SYS_HNDLR_CTRL — NVIC System Handler Control and State Register
  [18] USGFAULTEN — Usage fault handler enable
    0=NVIC_USGFAULT_DISABLE (Disable usage fault handler); 1=NVIC_USGFAULT_ENABLE (Enable usage fault handler)
  [17] BUSFAULTEN — Bus fault handler enable
    0=NVIC_BUSFAULT_DISABLE (Disable bus fault handler); 1=NVIC_BUSFAULT_ENABLE (Enable bus fault handler)
  [16] MEMFAULTEN — Memory management fault handler enable
    0=NVIC_MEMFAULT_DISABLE (Disable memory management fault handler); 1=NVIC_MEMFAULT_ENABLE (Enable memory management fault handler)
  [15] SVCALLPENDED — SVCall is pending or was started and replaced by a higher priority exception
    0=NVIC_SVCALL_CLRPEND (SVCall handler not pending); 1=NVIC_SVCALL_SETPEND (SVCall handler is pending)
  [14] BUSFAULTPENDED — Bus fault is pending or was started and replaced by a higher priority exception
    0=NVIC_BUSFAULT_CLRPEND (Bus fault handler not pending); 1=NVIC_BUSFAULT_SETPEND (Bus fault handler is pending)
  [13] MEMFAULTPENDED — Memory management fault is pending or was started and replaced by a higher priority exception
    0=NVIC_MEMFAULT_CLRPEND (Memory management fault handler not pending); 1=NVIC_MEMFAULT_SETPEND (Memory management fault handler is pending)
  [12] USGFAULTPENDED — Usage fault is pending or was started and replaced by a higher priority exception
    0=NVIC_USGFAULT_CLRPEND (Usagefault handler not pending); 1=NVIC_USGFAULT_SETPEND (Usage fault handler is pending)
  [11] SYSTICKACT — SYSTICK exception handler is active
    1=NVIC_SYSTICK_ACTIVE (SYSTICK exception handler is active)
  [10] PENDSVACT — PendSV exception handler is active
    1=NVIC_PENDSV_ACTIVE (PendSV exception handler is active)
  [8] MONITORACT — Debug monitor exception handler is active
    1=NVIC_MONITOR_ACTIVE (Debug monitor exception handler is active)
  [7] SVCALLACT — SVCall exception handler is active
    1=NVIC_SVCALL_ACTIVE (SVCall exception is active)
  [3] USGFAULTACT — Usage fault exception handler is active
    1=NVIC_USGFAULT_ACTIVE (Usage fault exception handler is active)
  [1] BUSFAULTACT — Bus fault exception handler is active
    1=NVIC_BUSFAULT_ACTIVE (Bus fault exception handler is active)
  [0] MEMFAULTACT — Memory management fault exception handler is active
    1=NVIC_MEMFAULT_ACTIVE (Memory management fault exception handler is active)
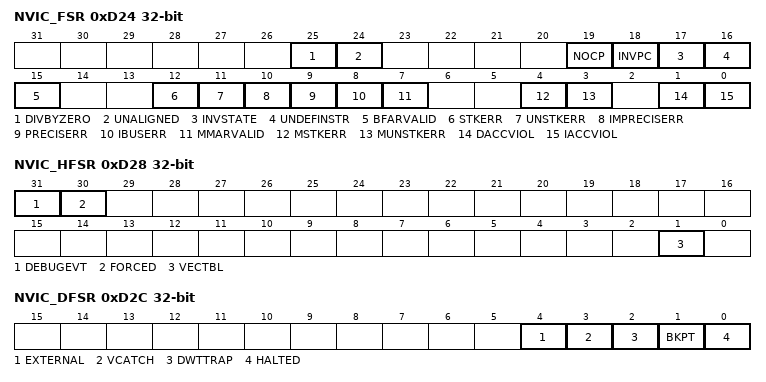
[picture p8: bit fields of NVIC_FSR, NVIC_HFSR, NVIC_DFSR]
0xD24 NVIC_FSR — NVIC Fault Status Register
  [25] DIVBYZERO — Indicates divide by zero will take place
  [24] UNALIGNED — Indicates unaligned access will take place
  [19] NOCP — Attempt to execute a coprocessor instruction
  [18] INVPC — Attempt to do exception with bad value in EXC_RETURN number
  [17] INVSTATE — Attempt to switch to invalid (e.g. ARM) state
  [16] UNDEFINSTR — Attempt to execute an undefined instruction
  [15] BFARVALID — Indicates if bus fault address register is valid
    0=NVIC_BFAR_INVALID (Bus fault address register is not valid); 1=NVIC_BFAR_VALID (Bus fault address register is valid)
  [12] STKERR — Indicates stacking error
  [11] UNSTKERR — Indicates unstacking error
  [10] IMPRECISERR — Indicates imprecise data access violation
  [9] PRECISERR — Indicates precise data access violation
  [8] IBUSERR — Indicates instruction access violation
  [7] MMARVALID — Indicates if memory management fault address register is valid
    0=NVIC_MMAR_INVALID (Memory management fault address register is not valid); 1=NVIC_MMAR_VALID (Memory management fault address register is valid)
  [4] MSTKERR — Indicates stacking error
  [3] MUNSTKERR — Indicates unstacking error
  [1] DACCVIOL — Indicates data access violation
  [0] IACCVIOL — Indicates instruction access violation
0xD28 NVIC_HFSR — NVIC Hard Fault Status Register
  [31] DEBUGEVT — Indicates hard fault is triggered by debug event
  [30] FORCED — Indicates hard fault is taken because of a lower priority (e.g., bus, memory management or usage) fault
  [1] VECTBL — Indicates hard fault is taken due to failed vector fetch
0xD2C NVIC_DFSR — NVIC Debug Fault Status Register
  [4] EXTERNAL — Indicates external debug request signal asserted
  [3] VCATCH — Indicates vector fetch occurred
  [2] DWTTRAP — Indicates DWT match occurred
  [1] BKPT — Indicates BKPT instruction executed
  [0] HALTED — Indicates halt requested by NVIC
0xD30 NVIC_MMAR — NVIC Memory Management Fault Address Register
0xD34 NVIC_BFAR — NVIC Bus Fault Address Register
0xEFC NVIC_SW_INT — NVIC Software Trigger Interrupt Register
  [7:0] INTID — The interrupt number to trigger
